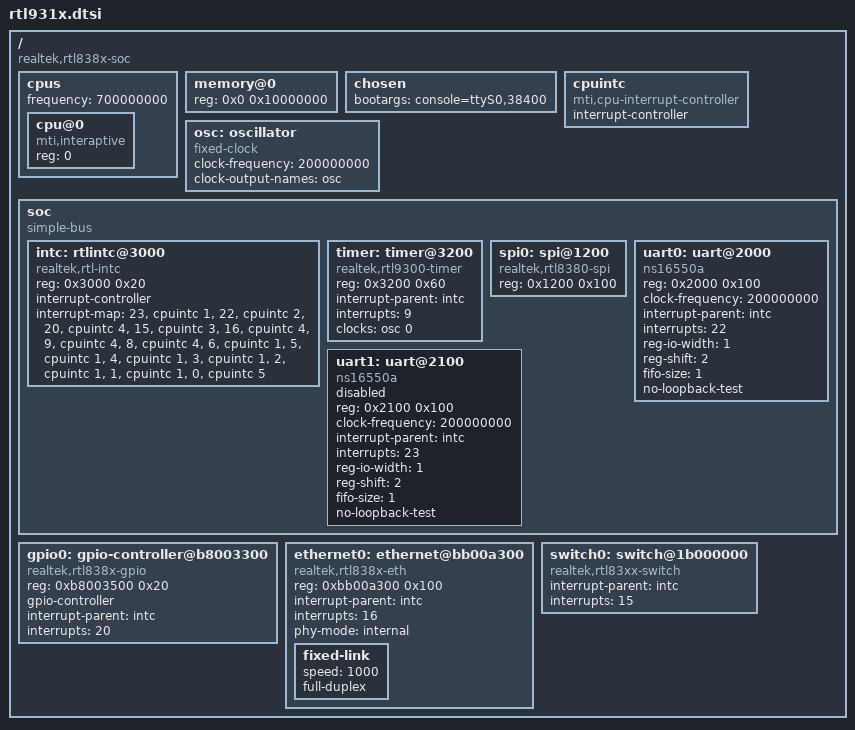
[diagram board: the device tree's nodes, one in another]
// SPDX-License-Identifier: GPL-2.0-or-later OR MIT

/ {
	#address-cells = <1>;
	#size-cells = <1>;
	
	compatible = "realtek,rtl838x-soc";

	cpus {
		#address-cells = <1>;
		#size-cells = <0>;
		frequency = <700000000>;

		cpu@0 {
			// try: 
			compatible = "mti,interaptive";
			//compatible = "mips,mips34Kc";
			reg = <0>;
		};
	};

	memory@0 {
		device_type = "memory";
		reg = <0x0 0x10000000>;
	};
	
	chosen {
		bootargs = "console=ttyS0,38400";
	};

	cpuintc: cpuintc {
		compatible = "mti,cpu-interrupt-controller";
		#address-cells = <0>;
		#interrupt-cells = <1>;
		interrupt-controller;
	};


	osc: oscillator {
		compatible = "fixed-clock";
		#clock-cells = <1>;
		clock-frequency  = <200000000>;
		clock-output-names = "osc";
	};
	
	soc: soc {
		compatible = "simple-bus";
		#address-cells = <1>;
		#size-cells = <1>;
		ranges = <0x0 0x18000000 0x10000>;

		intc: rtlintc@3000 {
			compatible = "realtek,rtl-intc";
			reg = <0x3000 0x20>;
			#address-cells = <0>;
			#interrupt-cells = <1>;
			interrupt-controller;
			interrupt-map =
				<23 &cpuintc 1>, /* UART1 */
				<22 &cpuintc 2>, /* UART0 */
				<20 &cpuintc 4>, /* GPIO_ABCD */
				/* <36 &cpuintc 1>,*/ /* USB_H2 */
				<15 &cpuintc 3>, /* SWCORE */
				<16 &cpuintc 4>, /* NIC */
				<9 &cpuintc 4>, /* WDT_IP2 */
				<8 &cpuintc 4>, /* WDT_IP1 */
				<6 &cpuintc 1>, /* TC6 */
				<5 &cpuintc 1>, /* TC5 */
				<4 &cpuintc 1>, /* TC4 */
				<3 &cpuintc 1>, /* TC3 */
				<2 &cpuintc 1>,  /* TC2 */
				<1 &cpuintc 1>, /* TC1 */
				<0 &cpuintc 5>; /* TC0 */
		};

		timer: timer@3200 {
			compatible = "realtek,rtl9300-timer";
			reg = <0x3200 0x60>;
			interrupt-parent = <&intc>;
			interrupts = <9>;
			interrupt-names = "ostimer";
			clocks = <&osc 0>;
		};

		spi0: spi@1200 {
			status = "okay";

			compatible = "realtek,rtl8380-spi";
			reg = <0x1200 0x100>;

			#address-cells = <1>;
			#size-cells = <0>;
		};

		uart0: uart@2000 {
			compatible = "ns16550a";
			reg = <0x2000 0x100>;

			clock-frequency = <200000000>;

			interrupt-parent = <&intc>;
			interrupts = <22>;

			reg-io-width = <1>;
			reg-shift = <2>;
			fifo-size = <1>;
			no-loopback-test;
		};

		uart1: uart@2100 {
			compatible = "ns16550a";
			reg = <0x2100 0x100>;

			clock-frequency = <200000000>;

			interrupt-parent = <&intc>;
			interrupts = <23>;

			reg-io-width = <1>;
			reg-shift = <2>;
			fifo-size = <1>;
			no-loopback-test;

			status = "disabled";
		};
	};

	gpio0: gpio-controller@b8003300 {
		compatible = "realtek,rtl838x-gpio";
		reg = <0xb8003500 0x20>;
		gpio-controller;
		#gpio-cells = <2>;
		interrupt-parent = <&intc>;
		interrupts = <20>;
	};

	ethernet0: ethernet@bb00a300 {
		status = "okay";
		compatible = "realtek,rtl838x-eth";
		reg = <0xbb00a300 0x100>;
		interrupt-parent = <&intc>;
		interrupts = <16>;
		#interrupt-cells = <1>;
		phy-mode = "internal";
		fixed-link {
			speed = <1000>;
			full-duplex;
		};
	};

	switch0: switch@1b000000 {
		compatible = "realtek,rtl83xx-switch";

		interrupt-parent = <&intc>;
		interrupts = <15>;
	};
};
